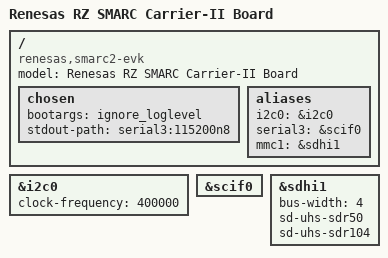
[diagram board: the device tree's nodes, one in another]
// SPDX-License-Identifier: (GPL-2.0-only OR BSD-2-Clause)
/*
 * Device Tree Source for the RZ SMARC Carrier-II Board.
 *
 * Copyright (C) 2024 Renesas Electronics Corp.
 */

/ {
	model = "Renesas RZ SMARC Carrier-II Board";
	compatible = "renesas,smarc2-evk";

	chosen {
		bootargs = "ignore_loglevel";
		stdout-path = "serial3:115200n8";
	};

	aliases {
		i2c0 = &i2c0;
		serial3 = &scif0;
		mmc1 = &sdhi1;
	};
};

&i2c0 {
	status = "okay";
	clock-frequency = <400000>;
};

&scif0 {
	status = "okay";
};

&sdhi1 {
	bus-width = <4>;
	sd-uhs-sdr50;
	sd-uhs-sdr104;

	status = "okay";
};
